# apollo3 register map
Vendor: Ambiq Micro; Series: Apollo; File version: 1.0
CPU: CM4 r1p0, little endian, MPU, FPU, 3 interrupt priority bits
Registers are 32-bit, read-write, reset 0x0 unless marked. A register's access mark holds for its fields unless they carry their own. Offsets are from the block's base; [hi:lo] are bit positions; {n}, {i} and the like mark numbered series; 'fields as' and 'values as' point back to an identical list.

## CTIMER (part 3 of 3) — Counter/Timer
Base 0x40008000
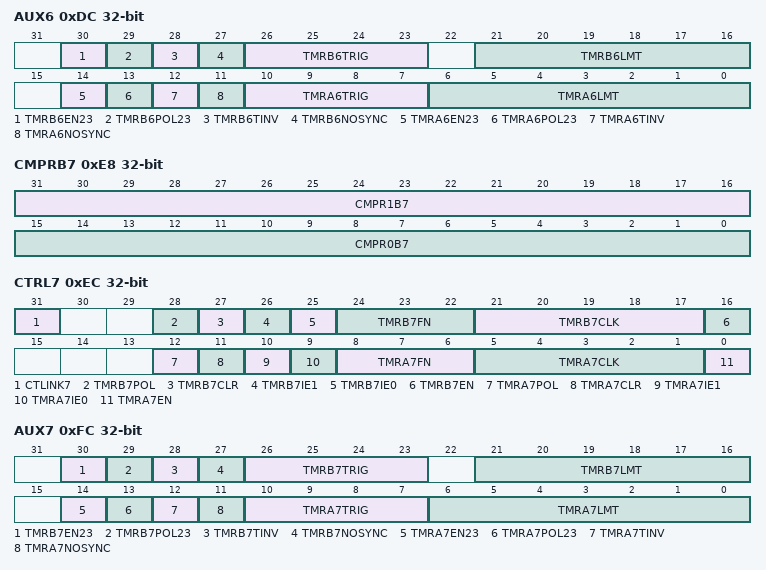
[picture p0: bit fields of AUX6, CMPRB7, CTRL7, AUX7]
0xDC AUX6 — Counter/Timer Auxiliary
  [30] TMRB6EN23 — Counter/Timer B6 Upper compare enable.
    1=DIS (Disable enhanced functions. value.); 0=EN (Enable enhanced functions. value.)
  [29] TMRB6POL23 — Upper output polarity
    0=NORM (Upper output normal polarity value.); 1=INV (Upper output inverted polarity. value.)
  [28] TMRB6TINV — Counter/Timer B6 Invert on trigger.
    0=DIS (Disable invert on trigger value.); 1=EN (Enable invert on trigger value.)
  [27] TMRB6NOSYNC — Source clock synchronization control.
    0=DIS (Synchronization on source clock value.); 1=NOSYNC (No synchronization on source clock value.)
  [26:23] TMRB6TRIG — Counter/Timer B6 Trigger Select.
    0=DIS (Trigger source is disabled. value.); 1=A6OUT (Trigger source is CTIMERA6 OUT. value.); 2=B3OUT (Trigger source is CTIMERB3 OUT. value.); 3=A3OUT (Trigger source is CTIMERA3 OUT. value.); 4=A4OUT (Trigger source is CTIMERA4 OUT. value.); 5=B4OUT (Trigger source is CTIMERB4 OUT. value.); 6=A1OUT (Trigger source is CTIMERA1 OUT. value.); 7=B1OUT (Trigger source is CTIMERB1 OUT. value.); 8=B3OUT2 (Trigger source is CTIMERB3 OUT2. value.); 9=A3OUT2 (Trigger source is CTIMERA3 OUT2. value.); 10=A2OUT2 (Trigger source is CTIMERA2 OUT2. value.); 11=B2OUT2 (Trigger source is CTIMERB2 OUT2. value.); 12=A6OUT2DUAL (Trigger source is CTIMERA6 OUT2, dual edge. value.); 13=A7OUT2DUAL (Trigger source is CTIMERA7 OUT2, dual edge. value.); 14=B0OUT2DUAL (Trigger source is CTIMERB0 OUT2, dual edge. value.); 15=A0OUT2DUAL (Trigger source is CTIMERA0 OUT2, dual edge. value.)
  [21:16] TMRB6LMT — Counter/Timer B6 Pattern Limit Count.
  [14] TMRA6EN23 — Counter/Timer A6 Upper compare enable.
    values as TMRB6EN23
  [13] TMRA6POL23 — Counter/Timer A6 Upper output polarity
    values as TMRB6POL23
  [12] TMRA6TINV — Counter/Timer A6 Invert on trigger.
    values as TMRB6TINV
  [11] TMRA6NOSYNC — Source clock synchronization control.
    values as TMRB6NOSYNC
  [10:7] TMRA6TRIG — Counter/Timer A6 Trigger Select.
    0=DIS (Trigger source is disabled. value.); 1=B6OUT (Trigger source is CTIMERB6 OUT. value.); 2=B3OUT (Trigger source is CTIMERB3 OUT. value.); 3=A3OUT (Trigger source is CTIMERA3 OUT. value.); 4=A5OUT (Trigger source is CTIMERA5 OUT. value.); 5=B5OUT (Trigger source is CTIMERB5 OUT. value.); 6=A1OUT (Trigger source is CTIMERA1 OUT. value.); 7=B1OUT (Trigger source is CTIMERB1 OUT. value.); 8=B3OUT2 (Trigger source is CTIMERB3 OUT2. value.); 9=A3OUT2 (Trigger source is CTIMERA3 OUT2. value.); 10=A2OUT2 (Trigger source is CTIMERA2 OUT2. value.); 11=B2OUT2 (Trigger source is CTIMERBb OUT2. value.); 12=A5OUT2DUAL (Trigger source is CTIMERA5 OUT2, dual edge. value.); 13=A7OUT2DUAL (Trigger source is CTIMERA7 OUT2, dual edge. value.); 14=B0OUT2DUAL (Trigger source is CTIMERB0 OUT2, dual edge. value.); 15=A0OUT2DUAL (Trigger source is CTIMERA0 OUT2, dual edge. value.)
  [6:0] TMRA6LMT — Counter/Timer A6 Pattern Limit Count.
0xE8 CMPRB7 — Counter/Timer B7 Compare Registers
  [31:16] CMPR1B7 — Counter/Timer B3 Compare Register 1.
  [15:0] CMPR0B7 — Counter/Timer B3 Compare Register 0.
0xEC CTRL7 — Counter/Timer Control
  [31] CTLINK7 — Counter/Timer A7/B7 Link bit.
    0=TWO_16BIT_TIMERS (Use A7/B7 timers as two independent 16-bit timers (default). value.); 1=32BIT_TIMER (Link A7/B7 timers into a single 32-bit timer. value.)
  [28] TMRB7POL — Counter/Timer B7 output polarity.
    0=NORMAL (The polarity of the TMRPINB7 pin is the same as the timer output. value.); 1=INVERTED (The polarity of the TMRPINB7 pin is the inverse of the timer output. value.)
  [27] TMRB7CLR — Counter/Timer B7 Clear bit.
    0=RUN (Allow counter/timer B7 to run value.); 1=CLEAR (Holds counter/timer B7 at 0x0000. value.)
  [26] TMRB7IE1 — Counter/Timer B7 Interrupt Enable bit for COMPR1.
    0=DIS (Disable counter/timer B7 from generating an interrupt based on COMPR1. value.); 1=EN (Enable counter/timer B7 to generate an interrupt based on COMPR1. value.)
  [25] TMRB7IE0 — Counter/Timer B7 Interrupt Enable bit for COMPR0.
    0=DIS (Disable counter/timer B7 from generating an interrupt based on COMPR0. value.); 1=EN (Enable counter/timer B7 to generate an interrupt based on COMPR0 value.)
  [24:22] TMRB7FN — Counter/Timer B7 Function Select.
    0=SINGLECOUNT (Single count (output toggles and sticks). Count to CMPR0B7, stop. value.); 1=REPEATEDCOUNT (Repeated count (periodic 1-clock-cycle-wide pulses). Count to CMPR0B7, restart. value.); 2=PULSE_ONCE (Pulse once (aka one-shot). Count to CMPR0B7, assert, count to CMPR1B7, deassert, stop. value.); 3=PULSE_CONT (Pulse continously. Count to CMPR0B7, assert, count to CMPR1B7, deassert, restart. value.); 4=SINGLEPATTERN (Single pattern. value.); 5=REPEATPATTERN (Repeated pattern. value.); 6=CONTINUOUS (Continuous run (aka Free Run). Count continuously. value.); 7=ALTPWN (Alternate PWM value.)
  [21:17] TMRB7CLK — Counter/Timer B7 Clock Select.
    0=TMRPIN (Clock source is TMRPINB. value.); 1=HFRC_DIV4 (Clock source is the HFRC / 4 value.); 2=HFRC_DIV16 (Clock source is HFRC / 16 value.); 3=HFRC_DIV256 (Clock source is HFRC / 256 value.); 4=HFRC_DIV1024 (Clock source is HFRC / 1024 value.); 5=HFRC_DIV4K (Clock source is HFRC / 4096 value.); 6=XT (Clock source is the XT (uncalibrated). value.); 7=XT_DIV2 (Clock source is XT / 2 value.); 8=XT_DIV16 (Clock source is XT / 16 value.); 9=XT_DIV128 (Clock source is XT / 128 value.); 10=LFRC_DIV2 (Clock source is LFRC / 2 value.); 11=LFRC_DIV32 (Clock source is LFRC / 32 value.); 12=LFRC_DIV1K (Clock source is LFRC / 1024 value.); 13=LFRC (Clock source is LFRC value.); 14=RTC_100HZ (Clock source is 100 Hz from the current RTC oscillator. value.); 15=HCLK (Clock source is HCLK. value.); 16=XT_DIV4 (Clock source is XT / 4 value.); 17=XT_DIV8 (Clock source is XT / 8 value.); 18=XT_DIV32 (Clock source is XT / 32 value.); 20=CTMRA7 (Clock source is CTIMERA7 OUT. value.); 21=CTMRA2 (Clock source is CTIMERA2 OUT. value.); 22=CTMRB2 (Clock source is CTIMERB2 OUT. value.); 23=CTMRA0 (Clock source is CTIMERA0 OUT. value.); 24=CTMRB0 (Clock source is CTIMERB0 OUT. value.); 25=CTMRB1 (Clock source is CTIMERB1 OUT. value.); 26=CTMRB3 (Clock source is CTIMERB3 OUT. value.); 27=CTMRB4 (Clock source is CTIMERB4 OUT. value.); 28=CTMRB5 (Clock source is CTIMERB5 OUT. value.); 29=BUCKBLE (Clock source is BLE buck converter TON pulses. value.); 30=BUCKB (Clock source is Memory buck converter TON pulses. value.); 31=BUCKA (Clock source is CPU buck converter TON pulses. value.)
  [16] TMRB7EN — Counter/Timer B7 Enable bit.
    0=DIS (Counter/Timer B7 Disable. value.); 1=EN (Counter/Timer B7 Enable. value.)
  [12] TMRA7POL — Counter/Timer A7 output polarity.
    0=NORMAL (The polarity of the TMRPINA7 pin is the same as the timer output. value.); 1=INVERTED (The polarity of the TMRPINA7 pin is the inverse of the timer output. value.)
  [11] TMRA7CLR — Counter/Timer A7 Clear bit.
    0=RUN (Allow counter/timer A7 to run value.); 1=CLEAR (Holds counter/timer A7 at 0x0000. value.)
  [10] TMRA7IE1 — Counter/Timer A7 Interrupt Enable bit based on COMPR1.
    0=DIS (Disable counter/timer A7 from generating an interrupt based on COMPR1. value.); 1=EN (Enable counter/timer A7 to generate an interrupt based on COMPR1. value.)
  [9] TMRA7IE0 — Counter/Timer A7 Interrupt Enable bit based on COMPR0.
    0=DIS (Disable counter/timer A7 from generating an interrupt based on COMPR0. value.); 1=EN (Enable counter/timer A7 to generate an interrupt based on COMPR0. value.)
  [8:6] TMRA7FN — Counter/Timer A7 Function Select.
    0=SINGLECOUNT (Single count (output toggles and sticks). Count to CMPR0A7, stop. value.); 1=REPEATEDCOUNT (Repeated count (periodic 1-clock-cycle-wide pulses). Count to CMPR0A7, restart. value.); 2=PULSE_ONCE (Pulse once (aka one-shot). Count to CMPR0A7, assert, count to CMPR1A7, deassert, stop. value.); 3=PULSE_CONT (Pulse continously. Count to CMPR0A7, assert, count to CMPR1A7, deassert, restart. value.); 4=SINGLEPATTERN (Single pattern. value.); 5=REPEATPATTERN (Repeated pattern. value.); 6=CONTINUOUS (Continuous run (aka Free Run). Count continuously. value.); 7=ALTPWN (Alternate PWM value.)
  [5:1] TMRA7CLK — Counter/Timer A7 Clock Select.
    0=TMRPIN (Clock source is TMRPINA. value.); 1=HFRC_DIV4 (Clock source is the HFRC / 4 value.); 2=HFRC_DIV16 (Clock source is HFRC / 16 value.); 3=HFRC_DIV256 (Clock source is HFRC / 256 value.); 4=HFRC_DIV1024 (Clock source is HFRC / 1024 value.); 5=HFRC_DIV4K (Clock source is HFRC / 4096 value.); 6=XT (Clock source is the XT (uncalibrated). value.); 7=XT_DIV2 (Clock source is XT / 2 value.); 8=XT_DIV16 (Clock source is XT / 16 value.); 9=XT_DIV128 (Clock source is XT / 128 value.); 10=LFRC_DIV2 (Clock source is LFRC / 2 value.); 11=LFRC_DIV32 (Clock source is LFRC / 32 value.); 12=LFRC_DIV1K (Clock source is LFRC / 1024 value.); 13=LFRC (Clock source is LFRC value.); 14=RTC_100HZ (Clock source is 100 Hz from the current RTC oscillator. value.); 15=HCLK (Clock source is HCLK. value.); 16=XT_DIV4 (Clock source is XT / 4 value.); 17=XT_DIV8 (Clock source is XT / 8 value.); 18=XT_DIV32 (Clock source is XT / 32 value.); 20=CTMRB7 (Clock source is CTIMERB7 OUT. value.); 21=CTMRA2 (Clock source is CTIMERA2 OUT. value.); 22=CTMRB2 (Clock source is CTIMERB2 OUT. value.); 23=CTMRA0 (Clock source is CTIMERA0 OUT. value.); 24=CTMRB0 (Clock source is CTIMERB0 OUT. value.); 25=CTMRB1 (Clock source is CTIMERB1 OUT. value.); 26=CTMRB3 (Clock source is CTIMERB3 OUT. value.); 27=CTMRB4 (Clock source is CTIMERB4 OUT. value.); 28=CTMRB5 (Clock source is CTIMERB5 OUT. value.); 29=BUCKBLE (Clock source is BLE buck converter TON pulses. value.); 30=BUCKB (Clock source is Memory buck converter TON pulses. value.); 31=BUCKA (Clock source is CPU buck converter TON pulses. value.)
  [0] TMRA7EN — Counter/Timer A7 Enable bit.
    0=DIS (Counter/Timer A7 Disable. value.); 1=EN (Counter/Timer A7 Enable. value.)
0xFC AUX7 — Counter/Timer Auxiliary
  [30] TMRB7EN23 — Counter/Timer B7 Upper compare enable.
    values as AUX6.TMRB6EN23
  [29] TMRB7POL23 — Upper output polarity
    values as AUX6.TMRB6POL23
  [28] TMRB7TINV — Counter/Timer B7 Invert on trigger.
    values as AUX6.TMRB6TINV
  [27] TMRB7NOSYNC — Source clock synchronization control.
    values as AUX6.TMRB6NOSYNC
  [26:23] TMRB7TRIG — Counter/Timer B7 Trigger Select.
    0=DIS (Trigger source is disabled. value.); 1=A7OUT (Trigger source is CTIMERA7 OUT. value.); 2=B3OUT (Trigger source is CTIMERB3 OUT. value.); 3=A3OUT (Trigger source is CTIMERA3 OUT. value.); 4=A5OUT (Trigger source is CTIMERA5 OUT. value.); 5=B5OUT (Trigger source is CTIMERB5 OUT. value.); 6=A2OUT (Trigger source is CTIMERA2 OUT. value.); 7=B2OUT (Trigger source is CTIMERB2 OUT. value.); 8=B3OUT2 (Trigger source is CTIMERB3 OUT2. value.); 9=A3OUT2 (Trigger source is CTIMERA3 OUT2. value.); 10=A2OUT2 (Trigger source is CTIMERA2 OUT2. value.); 11=B2OUT2 (Trigger source is CTIMERB2 OUT2. value.); 12=A6OUT2DUAL (Trigger source is CTIMERA6 OUT2, dual edge. value.); 13=A7OUT2DUAL (Trigger source is CTIMERA7 OUT2, dual edge. value.); 14=B1OUT2DUAL (Trigger source is CTIMERB1 OUT2, dual edge. value.); 15=A1OUT2DUAL (Trigger source is CTIMERA1 OUT2, dual edge. value.)
  [21:16] TMRB7LMT — Counter/Timer B7 Pattern Limit Count.
  [14] TMRA7EN23 — Counter/Timer A7 Upper compare enable.
    values as AUX6.TMRB6EN23
  [13] TMRA7POL23 — Counter/Timer A7 Upper output polarity
    values as AUX6.TMRB6POL23
  [12] TMRA7TINV — Counter/Timer A7 Invert on trigger.
    values as AUX6.TMRB6TINV
  [11] TMRA7NOSYNC — Source clock synchronization control.
    values as AUX6.TMRB6NOSYNC
  [10:7] TMRA7TRIG — Counter/Timer A7 Trigger Select.
    0=DIS (Trigger source is disabled. value.); 1=B7OUT (Trigger source is CTIMERB7 OUT. value.); 2=B3OUT (Trigger source is CTIMERB3 OUT. value.); 3=A3OUT (Trigger source is CTIMERA3 OUT. value.); 4=A1OUT (Trigger source is CTIMERA1 OUT. value.); 5=B1OUT (Trigger source is CTIMERB1 OUT. value.); 6=A4OUT (Trigger source is CTIMERA4 OUT. value.); 7=B4OUT (Trigger source is CTIMERB4 OUT. value.); 8=B3OUT2 (Trigger source is CTIMERB3 OUT2. value.); 9=A3OUT2 (Trigger source is CTIMERA3 OUT2. value.); 10=A2OUT2 (Trigger source is CTIMERA2 OUT2. value.); 11=B2OUT2 (Trigger source is CTIMERB2 OUT2. value.); 12=A6OUT2DUAL (Trigger source is CTIMERA6 OUT2, dual edge. value.); 13=A5OUT2DUAL (Trigger source is CTIMERA5 OUT2, dual edge. value.); 14=B4OUT2DUAL (Trigger source is CTIMERB4 OUT2, dual edge. value.); 15=A4OUT2DUAL (Trigger source is CTIMERA4 OUT2, dual edge. value.)
  [6:0] TMRA7LMT — Counter/Timer A7 Pattern Limit Count.
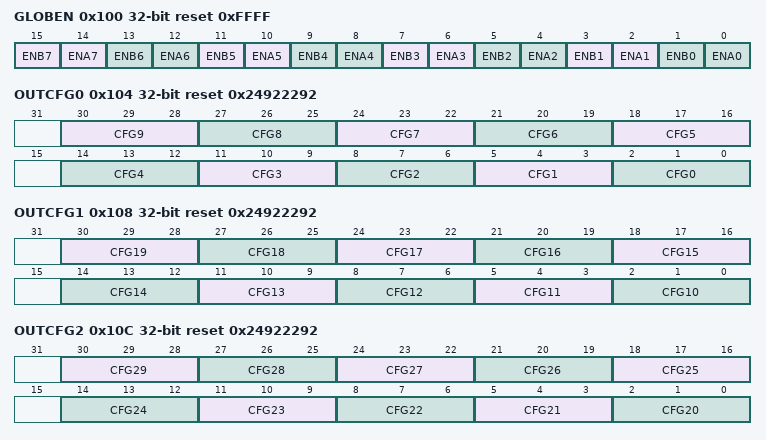
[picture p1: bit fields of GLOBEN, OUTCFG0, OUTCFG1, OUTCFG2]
0x100 GLOBEN reset 0xFFFF — Counter/Timer Global Enable
  [all] fields
    1=LCO (Use local enable. value.); 0=DIS (Disable CTIMER. value.)
  [15] ENB7 — Alternate enable for B7.
  [2n] ENA{n} (n=0..7) — Alternate enable for A{n}
  [13] ENB6 — Alternate enable for B6
  [11] ENB5 — Alternate enable for B5
  [9] ENB4 — Alternate enable for B4
  [7] ENB3 — Alternate enable for B3.
  [5] ENB2 — Alternate enable for B2
  [3] ENB1 — Alternate enable for B1
  [1] ENB0 — Alternate enable for B0
0x104 OUTCFG0 reset 0x24922292 — Counter/Timer Output Config 0
  [30:28] CFG9 — Pad output 9 configuration
    7=A7OUT2 (Output is A7OUT2. value.); 6=A6OUT2 (Output is A6OUT2. value.); 5=B0OUT (Output is B0OUT. value.); 4=A4OUT (Output is A4OUT. value.); 3=A2OUT (Output is A2OUT. value.); 2=A2OUT2 (Output is A2OUT2 value.); 1=ONE (Force output to 1. value.); 0=ZERO (Force output to 0 value.)
  [27:25] CFG8 — Pad output 8 configuration
    7=A7OUT2 (Output is A7OUT2. value.); 6=A6OUT2 (Output is A6OUT2. value.); 5=B6OUT (Output is B6OUT. value.); 4=A4OUT2 (Output is A4OUT2. value.); 3=A3OUT2 (Output is A3OUT. value.); 2=A2OUT (Output is A2OUT value.); 1=ONE (Force output to 1. value.); 0=ZERO (Force output to 0 value.)
  [24:22] CFG7 — Pad output 7 configuration
    7=A7OUT2 (Output is A7OUT2. value.); 6=A6OUT2 (Output is A6OUT2. value.); 5=A7OUT (Output is A7OUT. value.); 4=B5OUT (Output is B5OUT. value.); 3=B1OUT (Output is B1OUT. value.); 2=B1OUT2 (Output is B1OUT2 value.); 1=ONE (Force output to 1. value.); 0=ZERO (Force output to 0 value.)
  [21:19] CFG6 — Pad output 6 configuration
    7=A7OUT2 (Output is A7OUT2. value.); 6=A6OUT2 (Output is A6OUT2. value.); 5=B7OUT (Output is B7OUT. value.); 4=B5OUT2 (Output is B5OUT2. value.); 3=A1OUT (Output is A1OUT. value.); 2=B1OUT (Output is B1OUT value.); 1=ONE (Force output to 1. value.); 0=ZERO (Force output to 0 value.)
  [18:16] CFG5 — Pad output 5 configuration
    7=A7OUT2 (Output is A7OUT2. value.); 6=A6OUT2 (Output is A6OUT2. value.); 5=A7OUT (Output is A7OUT. value.); 4=B6OUT (Output is A5OUT. value.); 3=A1OUT (Output is A1OUT. value.); 2=A1OUT2 (Output is A1OUT2 value.); 1=ONE (Force output to 1. value.); 0=ZERO (Force output to 0 value.)
  [14:12] CFG4 — Pad output 4 configuration
    7=A7OUT2 (Output is A7OUT2. value.); 6=A6OUT2 (Output is A6OUT2. value.); 5=B5OUT (Output is B5OUT. value.); 4=A5OUT2 (Output is A5OUT2. value.); 3=A2OUT2 (Output is A2OUT2. value.); 2=A1OUT (Output is A1OUT value.); 1=ONE (Force output to 1. value.); 0=ZERO (Force output to 0 value.)
  [11:9] CFG3 — Pad output 3 configuration
    7=A7OUT2 (Output is A7OUT2. value.); 6=A6OUT2 (Output is A6OUT2. value.); 5=A6OUT (Output is A6OUT. value.); 4=A1OUT (Output is A1OUT. value.); 3=B0OUT (Output is B0OUT. value.); 2=B0OUT2 (Output is B0OUT2 value.); 1=ONE (Force output to 1. value.); 0=ZERO (Force output to 0 value.)
  [8:6] CFG2 — Pad output 2 configuration
    7=A7OUT2 (Output is A7OUT2. value.); 6=A6OUT2 (Output is A6OUT2. value.); 5=A7OUT (Output is A7OUT. value.); 4=B6OUT2 (Output is B6OUT2. value.); 3=B1OUT2 (Output is B1OUT2. value.); 2=B0OUT (Output is B0OUT value.); 1=ONE (Force output to 1. value.); 0=ZERO (Force output to 0 value.)
  [5:3] CFG1 — Pad output 1 configuration
    7=A7OUT2 (Output is A7OUT2. value.); 6=A6OUT2 (Output is A6OUT2. value.); 5=B7OUT2 (Output is B7OUT2. value.); 4=A5OUT (Output is A5OUT. value.); 3=A0OUT (Output is A0OUT. value.); 2=A0OUT2 (Output is A0OUT2 value.); 1=ONE (Force output to 1. value.); 0=ZERO (Force output to 0 value.)
  [2:0] CFG0 — Pad output 0 configuration
    7=A7OUT2 (Output is A7OUT2. value.); 6=A6OUT2 (Output is A6OUT2. value.); 5=A6OUT (Output is A6OUT. value.); 4=A5OUT2 (Output is A5OUT2. value.); 3=B2OUT2 (Output is B2OUT2. value.); 2=A0OUT (Output is A0OUT value.); 1=ONE (Force output to 1. value.); 0=ZERO (Force output to 0 value.)
0x108 OUTCFG1 reset 0x24922292 — Counter/Timer Output Config 1
  [30:28] CFG19 — Pad output 19 configuration
    7=A7OUT2 (Output is A7OUT2. value.); 6=A6OUT2 (Output is A6OUT2. value.); 5=B1OUT2 (Output is B1OUT2. value.); 4=B4OUT (Output is B4OUT. value.); 3=A2OUT (Output is A2OUT. value.); 2=B4OUT2 (Output is B4OUT2 value.); 1=ONE (Force output to 1. value.); 0=ZERO (Force output to 0 value.)
  [27:25] CFG18 — Pad output 18 configuration
    7=A7OUT2 (Output is A7OUT2. value.); 6=A6OUT2 (Output is A6OUT2. value.); 5=A3OUT2 (Output is A3OUT2. value.); 4=A0OUT (Output is A0OUT. value.); 3=B0OUT (Output is B0OUT. value.); 2=B4OUT (Output is B4OUT value.); 1=ONE (Force output to 1. value.); 0=ZERO (Force output to 0 value.)
  [24:22] CFG17 — Pad output 17 configuration
    7=A7OUT2 (Output is A7OUT2. value.); 6=A6OUT2 (Output is A6OUT2. value.); 5=A1OUT2 (Output is A1OUT2. value.); 4=A4OUT (Output is A4OUT. value.); 3=B7OUT (Output is B7OUT. value.); 2=A4OUT2 (Output is A4OUT2 value.); 1=ONE (Force output to 1. value.); 0=ZERO (Force output to 0 value.)
  [21:19] CFG16 — Pad output 16 configuration
    7=A7OUT2 (Output is A7OUT2. value.); 6=A6OUT2 (Output is A6OUT2. value.); 5=B3OUT2 (Output is B3OUT2. value.); 4=A0OUT2 (Output is A0OUT2. value.); 3=A0OUT (Output is A0OUT. value.); 2=A4OUT (Output is A4OUT value.); 1=ONE (Force output to 1. value.); 0=ZERO (Force output to 0 value.)
  [18:16] CFG15 — Pad output 15 configuration
    7=A7OUT2 (Output is A7OUT2. value.); 6=A6OUT2 (Output is A6OUT2. value.); 5=A4OUT2 (Output is A4OUT2. value.); 4=A7OUT (Output is B1OUT. value.); 3=B3OUT (Output is B3OUT. value.); 2=B3OUT2 (Output is B3OUT2 value.); 1=ONE (Force output to 1. value.); 0=ZERO (Force output to 0 value.)
  [14:12] CFG14 — Pad output 14 configuration
    7=A7OUT2 (Output is A7OUT2. value.); 6=A6OUT2 (Output is A6OUT2. value.); 5=A7OUT (Output is A7OUT. value.); 4=B7OUT2 (Output is B7OUT2. value.); 3=B1OUT (Output is B1OUT. value.); 2=B3OUT (Output is B3OUT value.); 1=ONE (Force output to 1. value.); 0=ZERO (Force output to 0 value.)
  [11:9] CFG13 — Pad output 13 configuration
    7=A7OUT2 (Output is A7OUT2. value.); 6=A6OUT2 (Output is A6OUT2. value.); 5=B4OUT2 (Output is B4OUT2. value.); 4=A6OUT (Output is B1OUT. value.); 3=A3OUT (Output is A3OUT. value.); 2=A3OUT2 (Output is A3OUT2 value.); 1=ONE (Force output to 1. value.); 0=ZERO (Force output to 0 value.)
  [8:6] CFG12 — Pad output 12 configuration
    7=A7OUT2 (Output is A7OUT2. value.); 6=A6OUT2 (Output is A6OUT2. value.); 5=B6OUT2 (Output is B6OUT2. value.); 4=B0OUT2 (Output is B0OUT2. value.); 3=B1OUT (Output is B1OUT. value.); 2=A3OUT (Output is A3OUT value.); 1=ONE (Force output to 1. value.); 0=ZERO (Force output to 0 value.)
  [5:3] CFG11 — Pad output 11 configuration
    7=A7OUT2 (Output is A7OUT2. value.); 6=A6OUT2 (Output is A6OUT2. value.); 5=B5OUT2 (Output is B5OUT2. value.); 4=B4OUT (Output is B4OUT. value.); 3=B2OUT (Output is B2OUT. value.); 2=B2OUT2 (Output is B2OUT2 value.); 1=ONE (Force output to 1. value.); 0=ZERO (Force output to 0 value.)
  [2:0] CFG10 — Pad output 10 configuration
    7=A7OUT2 (Output is A7OUT2. value.); 6=A6OUT2 (Output is A6OUT2. value.); 5=A6OUT (Output is A6OUT. value.); 4=B4OUT2 (Output is B4OUT2. value.); 3=B3OUT2 (Output is B3OUT2. value.); 2=B2OUT (Output is B2OUT value.); 1=ONE (Force output to 1. value.); 0=ZERO (Force output to 0 value.)
0x10C OUTCFG2 reset 0x24922292 — Counter/Timer Output Config 2
  [30:28] CFG29 — Pad output 29 configuration
    7=A7OUT2 (Output is A7OUT2. value.); 6=A6OUT2 (Output is A6OUT2. value.); 5=A3OUT2 (Output is A3OUT2. value.); 4=A7OUT (Output is A7OUT. value.); 3=A1OUT (Output is A1OUT. value.); 2=B5OUT2 (Output is B5OUT2 value.); 1=ONE (Force output to 1. value.); 0=ZERO (Force output to 0 value.)
  [27:25] CFG28 — Pad output 28 configuration
    7=A7OUT2 (Output is A7OUT2. value.); 6=A6OUT2 (Output is A6OUT2. value.); 5=B0OUT2 (Output is B0OUT2. value.); 4=A5OUT2 (Output is A5OUT2. value.); 3=A3OUT (Output is A3OUT. value.); 2=A7OUT (Output is A7OUT value.); 1=ONE (Force output to 1. value.); 0=ZERO (Force output to 0 value.)
  [24:22] CFG27 — Pad output 27 configuration
    7=A7OUT2 (Output is A7OUT2. value.); 6=A6OUT2 (Output is A6OUT2. value.); 5=B2OUT2 (Output is B2OUT2. value.); 4=B6OUT (Output is B6OUT. value.); 3=A1OUT (Output is A1OUT. value.); 2=B6OUT2 (Output is B6OUT2 value.); 1=ONE (Force output to 1. value.); 0=ZERO (Force output to 0 value.)
  [21:19] CFG26 — Pad output 26 configuration
    7=A7OUT2 (Output is A7OUT2. value.); 6=A6OUT2 (Output is A6OUT2. value.); 5=A1OUT2 (Output is A1OUT2. value.); 4=A5OUT (Output is A5OUT. value.); 3=B2OUT (Output is B2OUT. value.); 2=B6OUT (Output is B6OUT value.); 1=ONE (Force output to 1. value.); 0=ZERO (Force output to 0 value.)
  [18:16] CFG25 — Pad output 25 configuration
    7=A7OUT2 (Output is A7OUT2. value.); 6=A6OUT2 (Output is A6OUT2. value.); 5=A2OUT2 (Output is A2OUT2. value.); 4=A6OUT (Output is A6OUT. value.); 3=B2OUT (Output is B2OUT. value.); 2=B4OUT2 (Output is B4OUT2 value.); 1=ONE (Force output to 1. value.); 0=ZERO (Force output to 0 value.)
  [14:12] CFG24 — Pad output 24 configuration
    7=A7OUT2 (Output is A7OUT2. value.); 6=A6OUT2 (Output is A6OUT2. value.); 5=B1OUT2 (Output is B1OUT2. value.); 4=A1OUT (Output is A1OUT. value.); 3=A2OUT (Output is A2OUT. value.); 2=A6OUT (Output is A6OUT value.); 1=ONE (Force output to 1. value.); 0=ZERO (Force output to 0 value.)
  [11:9] CFG23 — Pad output 23 configuration
    7=A7OUT2 (Output is A7OUT2. value.); 6=A6OUT2 (Output is A6OUT2. value.); 5=B0OUT2 (Output is B0OUT2. value.); 4=A5OUT (Output is A5OUT. value.); 3=A7OUT (Output is B1OUT. value.); 2=B5OUT2 (Output is B5OUT2 value.); 1=ONE (Force output to 1. value.); 0=ZERO (Force output to 0 value.)
  [8:6] CFG22 — Pad output 22 configuration
    7=A7OUT2 (Output is A7OUT2. value.); 6=A6OUT2 (Output is A6OUT2. value.); 5=A2OUT2 (Output is A2OUT2. value.); 4=A1OUT (Output is A1OUT. value.); 3=A6OUT (Output is B1OUT. value.); 2=B5OUT (Output is B5OUT value.); 1=ONE (Force output to 1. value.); 0=ZERO (Force output to 0 value.)
  [5:3] CFG21 — Pad output 21 configuration
    7=A7OUT2 (Output is A7OUT2. value.); 6=A6OUT2 (Output is A6OUT2. value.); 5=A0OUT2 (Output is A0OUT2. value.); 4=B5OUT (Output is B5OUT. value.); 3=A1OUT (Output is A1OUT. value.); 2=A5OUT2 (Output is A5OUT2 value.); 1=ONE (Force output to 1. value.); 0=ZERO (Force output to 0 value.)
  [2:0] CFG20 — Pad output 20 configuration
    7=A7OUT2 (Output is A7OUT2. value.); 6=A6OUT2 (Output is A6OUT2. value.); 5=B2OUT2 (Output is B2OUT2. value.); 4=A1OUT2 (Output is A1OUT2. value.); 3=A1OUT (Output is A1OUT. value.); 2=A5OUT (Output is A5OUT value.); 1=ONE (Force output to 1. value.); 0=ZERO (Force output to 0 value.)
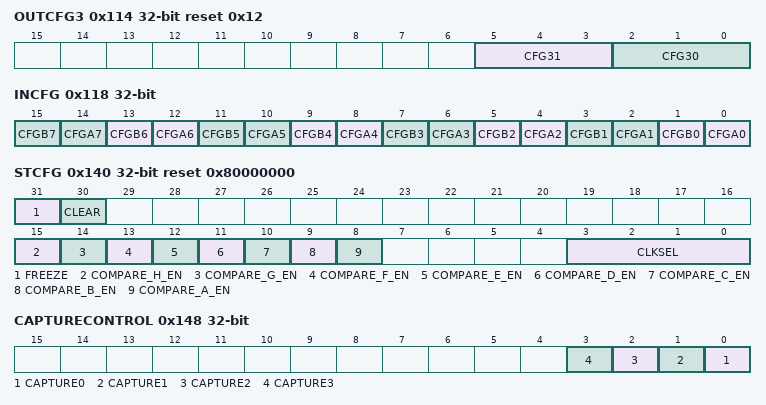
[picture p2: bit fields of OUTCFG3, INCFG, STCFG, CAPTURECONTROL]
0x114 OUTCFG3 reset 0x12 — Counter/Timer Output Config 3
  [5:3] CFG31 — Pad output 31 configuration
    7=A7OUT2 (Output is A7OUT2. value.); 6=A6OUT2 (Output is A6OUT2. value.); 5=B3OUT2 (Output is B3OUT2. value.); 4=B7OUT (Output is B7OUT. value.); 3=A6OUT (Output is A6OUT. value.); 2=B7OUT2 (Output is B7OUT2 value.); 1=ONE (Force output to 1. value.); 0=ZERO (Force output to 0 value.)
  [2:0] CFG30 — Pad output 30 configuration
    7=A7OUT2 (Output is A7OUT2. value.); 6=A6OUT2 (Output is A6OUT2. value.); 5=A0OUT2 (Output is A0OUT2. value.); 4=A4OUT2 (Output is A4OUT2. value.); 3=B3OUT (Output is B3OUT. value.); 2=B7OUT (Output is B7OUT value.); 1=ONE (Force output to 1. value.); 0=ZERO (Force output to 0 value.)
0x118 INCFG — Counter/Timer Input Config
  [2n+1] CFGB{n} (n=0..7) — CTIMER B{n} input configuration
    1=CT{4n+3} (Input is CT{4n+3} value.); 0=CT{4n+2} (Input is CT{4n+2} value.)
  [2n] CFGA{n} (n=0..7) — CTIMER A{n} input configuration
    1=CT{4n+1} (Input is CT{4n+1} value.); 0=CT{4n} (Input is CT{4n} value.)
0x140 STCFG reset 0x80000000 — Configuration Register
  [31] FREEZE — Set this bit to one to freeze the clock input to the COUNTER register. Once frozen, the value can be safely written from the MCU. Unfreeze to resume.
    0=THAW (Let the COUNTER register run on its input clock. value.); 1=FREEZE (Stop the COUNTER register for loading. value.)
  [30] CLEAR — Set this bit to one to clear the System Timer register. If this bit is set to '1', the system timer register will stay cleared. It needs to be set to '0' for the system timer to start running.
    0=RUN (Let the COUNTER register run on its input clock. value.); 1=CLEAR (Stop the COUNTER register for loading. value.)
  [15] COMPARE_H_EN — Selects whether compare is enabled for the corresponding SCMPR register. If compare is enabled, the interrupt status is set once the comparision is met.
    0=DISABLE (Compare H disabled. value.); 1=ENABLE (Compare H enabled. value.)
  [14] COMPARE_G_EN — Selects whether compare is enabled for the corresponding SCMPR register. If compare is enabled, the interrupt status is set once the comparision is met.
    0=DISABLE (Compare G disabled. value.); 1=ENABLE (Compare G enabled. value.)
  [13] COMPARE_F_EN — Selects whether compare is enabled for the corresponding SCMPR register. If compare is enabled, the interrupt status is set once the comparision is met.
    0=DISABLE (Compare F disabled. value.); 1=ENABLE (Compare F enabled. value.)
  [12] COMPARE_E_EN — Selects whether compare is enabled for the corresponding SCMPR register. If compare is enabled, the interrupt status is set once the comparision is met.
    0=DISABLE (Compare E disabled. value.); 1=ENABLE (Compare E enabled. value.)
  [11] COMPARE_D_EN — Selects whether compare is enabled for the corresponding SCMPR register. If compare is enabled, the interrupt status is set once the comparision is met.
    0=DISABLE (Compare D disabled. value.); 1=ENABLE (Compare D enabled. value.)
  [10] COMPARE_C_EN — Selects whether compare is enabled for the corresponding SCMPR register. If compare is enabled, the interrupt status is set once the comparision is met.
    0=DISABLE (Compare C disabled. value.); 1=ENABLE (Compare C enabled. value.)
  [9] COMPARE_B_EN — Selects whether compare is enabled for the corresponding SCMPR register. If compare is enabled, the interrupt status is set once the comparision is met.
    0=DISABLE (Compare B disabled. value.); 1=ENABLE (Compare B enabled. value.)
  [8] COMPARE_A_EN — Selects whether compare is enabled for the corresponding SCMPR register. If compare is enabled, the interrupt status is set once the comparision is met.
    0=DISABLE (Compare A disabled. value.); 1=ENABLE (Compare A enabled. value.)
  [3:0] CLKSEL — Selects an appropriate clock source and divider to use for the System Timer clock.
    0=NOCLK (No clock enabled. value.); 1=HFRC_DIV16 (3MHz from the HFRC clock divider. value.); 2=HFRC_DIV256 (187.5KHz from the HFRC clock divider. value.); 3=XTAL_DIV1 (32768Hz from the crystal oscillator. value.); 4=XTAL_DIV2 (16384Hz from the crystal oscillator. value.); 5=XTAL_DIV32 (1024Hz from the crystal oscillator. value.); 6=LFRC_DIV1 (Approximately 1KHz from the LFRC oscillator (uncalibrated). value.); 7=CTIMER0A (Use CTIMER 0 section A as a prescaler for the clock source. value.); 8=CTIMER0B (Use CTIMER 0 section B (or A and B linked together) as a prescaler for the clock source. value.)
0x144 STTMR — System Timer Count Register (Real Time Counter)
  [31:0] STTMR — Value of the 32-bit counter as it ticks over.
0x148 CAPTURECONTROL
  [all] fields
    0=DISABLE (Capture function disabled. value.); 1=ENABLE (Capture function enabled. value.)
  [n] CAPTURE{n} (n=0..3) — Selects whether capture is enabled for the specified capture register.
0x150 SCMPR0 — Compare Register A
  [31:0] SCMPR0 — Compare this value to the value in the COUNTER register according to the match criterion, as selected in the COMPARE_A_EN bit in the REG_CTIMER_STCGF register.
0x154 SCMPR1 — Compare Register B
  [31:0] SCMPR1 — Compare this value to the value in the COUNTER register according to the match criterion, as selected in the COMPARE_B_EN bit in the REG_CTIMER_STCGF register.
0x158 SCMPR2 — Compare Register C
  [31:0] SCMPR2 — Compare this value to the value in the COUNTER register according to the match criterion, as selected in the COMPARE_C_EN bit in the REG_CTIMER_STCGF register.
0x15C SCMPR3 — Compare Register D
  [31:0] SCMPR3 — Compare this value to the value in the COUNTER register according to the match criterion, as selected in the COMPARE_D_EN bit in the REG_CTIMER_STCGF register.
0x160 SCMPR4 — Compare Register E
  [31:0] SCMPR4 — Compare this value to the value in the COUNTER register according to the match criterion, as selected in the COMPARE_E_EN bit in the REG_CTIMER_STCGF register.
0x164 SCMPR5 — Compare Register F
  [31:0] SCMPR5 — Compare this value to the value in the COUNTER register according to the match criterion, as selected in the COMPARE_F_EN bit in the REG_CTIMER_STCGF register.
0x168 SCMPR6 — Compare Register G
  [31:0] SCMPR6 — Compare this value to the value in the COUNTER register according to the match criterion, as selected in the COMPARE_G_EN bit in the REG_CTIMER_STCGF register.
0x16C SCMPR7 — Compare Register H
  [31:0] SCMPR7 — Compare this value to the value in the COUNTER register according to the match criterion, as selected in the COMPARE_H_EN bit in the REG_CTIMER_STCGF register.
0x1E0 SCAPT0 — Capture Register A
  [31:0] SCAPT0 — Whenever the event is detected, the value in the COUNTER is copied into this register and the corresponding interrupt status bit is set.
0x1E4 SCAPT1 — Capture Register B
  [31:0] SCAPT1 — Whenever the event is detected, the value in the COUNTER is copied into this register and the corresponding interrupt status bit is set.
0x1E8 SCAPT2 — Capture Register C
  [31:0] SCAPT2 — Whenever the event is detected, the value in the COUNTER is copied into this register and the corresponding interrupt status bit is set.
0x1EC SCAPT3 — Capture Register D
  [31:0] SCAPT3 — Whenever the event is detected, the value in the COUNTER is copied into this register and the corresponding interrupt status bit is set.
0x1F0 SNVR0 — System Timer NVRAM_A Register
  [31:0] SNVR0 — Value of the 32-bit counter as it ticks over.
0x1F4 SNVR1 — System Timer NVRAM_B Register
  [31:0] SNVR1 — Value of the 32-bit counter as it ticks over.
0x1F8 SNVR2 — System Timer NVRAM_C Register
  [31:0] SNVR2 — Value of the 32-bit counter as it ticks over.
0x1FC SNVR3 — System Timer NVRAM_D Register
  [31:0] SNVR3 — Value of the 32-bit counter as it ticks over.
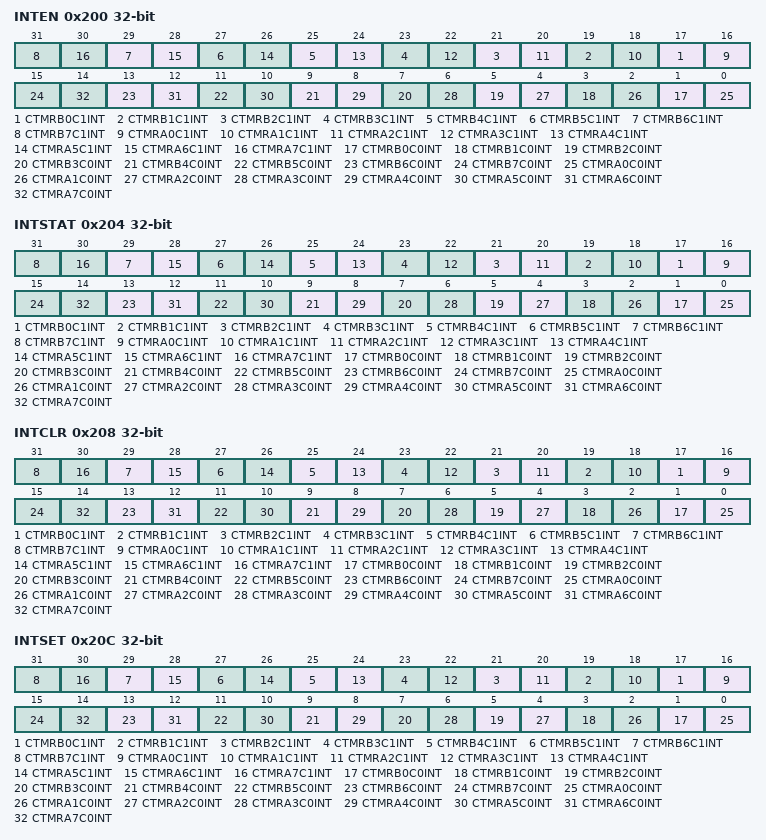
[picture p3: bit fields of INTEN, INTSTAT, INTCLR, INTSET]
0x200 INTEN — Counter/Timer Interrupts: Enable
  [2n+17] CTMRB{n}C1INT (n=0..7) — Counter/Timer B{n} interrupt based on COMPR1.
  [2n+16] CTMRA{n}C1INT (n=0..7) — Counter/Timer A{n} interrupt based on COMPR1.
  [2n+1] CTMRB{n}C0INT (n=0..7) — Counter/Timer B{n} interrupt based on COMPR0.
  [2n] CTMRA{n}C0INT (n=0..7) — Counter/Timer A{n} interrupt based on COMPR0.
0x204 INTSTAT — Counter/Timer Interrupts: Status
  fields as INTEN
0x208 INTCLR — Counter/Timer Interrupts: Clear
  fields as INTEN
0x20C INTSET — Counter/Timer Interrupts: Set
  fields as INTEN
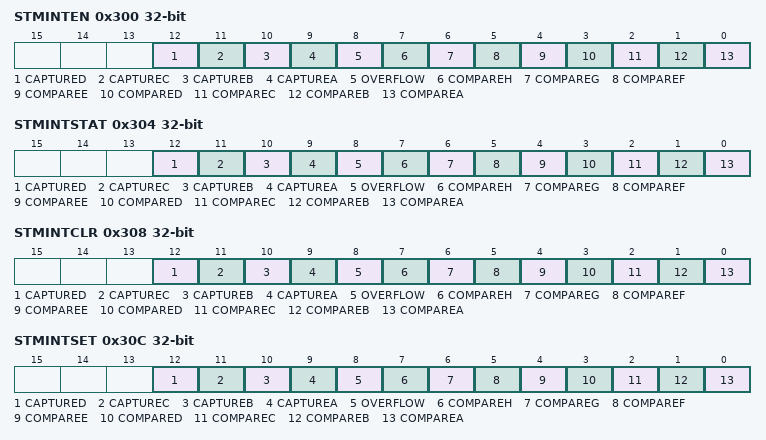
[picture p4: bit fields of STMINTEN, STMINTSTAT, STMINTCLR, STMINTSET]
0x300 STMINTEN — STIMER Interrupt registers: Enable
  [12] CAPTURED — CAPTURE register D has grabbed the value in the counter
    1=CAPD_INT (Capture D interrupt status bit was set. value.)
  [11] CAPTUREC — CAPTURE register C has grabbed the value in the counter
    1=CAPC_INT (CAPTURE C interrupt status bit was set. value.)
  [10] CAPTUREB — CAPTURE register B has grabbed the value in the counter
    1=CAPB_INT (CAPTURE B interrupt status bit was set. value.)
  [9] CAPTUREA — CAPTURE register A has grabbed the value in the counter
    1=CAPA_INT (CAPTURE A interrupt status bit was set. value.)
  [8] OVERFLOW — COUNTER over flowed from 0xFFFFFFFF back to 0x00000000.
    1=OFLOW_INT (Overflow interrupt status bit was set. value.)
  [7] COMPAREH — COUNTER is greater than or equal to COMPARE register H.
    1=COMPARED (COUNTER greater than or equal to COMPARE register. value.)
  [6] COMPAREG — COUNTER is greater than or equal to COMPARE register G.
    values as COMPAREH
  [5] COMPAREF — COUNTER is greater than or equal to COMPARE register F.
    values as COMPAREH
  [4] COMPAREE — COUNTER is greater than or equal to COMPARE register E.
    values as COMPAREH
  [3] COMPARED — COUNTER is greater than or equal to COMPARE register D.
    values as COMPAREH
  [2] COMPAREC — COUNTER is greater than or equal to COMPARE register C.
    values as COMPAREH
  [1] COMPAREB — COUNTER is greater than or equal to COMPARE register B.
    values as COMPAREH
  [0] COMPAREA — COUNTER is greater than or equal to COMPARE register A.
    values as COMPAREH
0x304 STMINTSTAT — STIMER Interrupt registers: Status
  fields as STMINTEN
0x308 STMINTCLR — STIMER Interrupt registers: Clear
  fields as STMINTEN
0x30C STMINTSET — STIMER Interrupt registers: Set
  fields as STMINTEN
